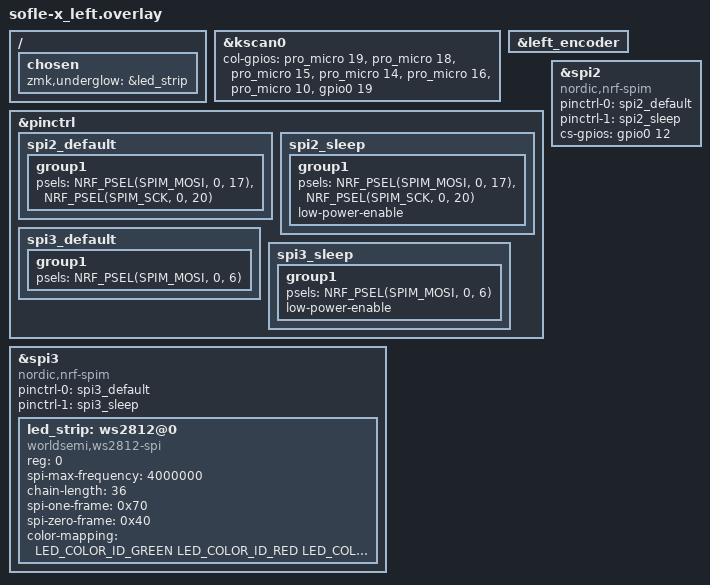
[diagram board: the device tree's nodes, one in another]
/*
 * Copyright (c) 2020 Ryan Cross
 *
 * SPDX-License-Identifier: MIT
 */

#include "sofle-x.dtsi"

&kscan0 {
    col-gpios
        = <&pro_micro 19 GPIO_ACTIVE_HIGH>
        , <&pro_micro 18 GPIO_ACTIVE_HIGH>
        , <&pro_micro 15 GPIO_ACTIVE_HIGH>
        , <&pro_micro 14 GPIO_ACTIVE_HIGH>
        , <&pro_micro 16 GPIO_ACTIVE_HIGH>
        , <&pro_micro 10 GPIO_ACTIVE_HIGH>
        , <&gpio0 19 GPIO_ACTIVE_HIGH>
        ;
};

&left_encoder {
    status = "okay";
};

#include <dt-bindings/led/led.h>


&pinctrl {
    spi2_default: spi2_default {
        group1 {
            psels = <NRF_PSEL(SPIM_MOSI, 0, 17)>,
            <NRF_PSEL(SPIM_SCK, 0, 20)>;
        };
    };
    spi2_sleep: spi2_sleep {
        group1 {
            psels = <NRF_PSEL(SPIM_MOSI, 0, 17)>,
            <NRF_PSEL(SPIM_SCK, 0, 20)>;
            low-power-enable;
        };
    };
};


lpm_view_spi: &spi2 {
    compatible = "nordic,nrf-spim";
    pinctrl-0 = <&spi2_default>;
    pinctrl-1 = <&spi2_sleep>;
    pinctrl-names = "default", "sleep";
    cs-gpios = <&gpio0 12 GPIO_ACTIVE_HIGH>;
};

nice_view_spi: &spi2 {
    compatible = "nordic,nrf-spim";
    pinctrl-0 = <&spi2_default>;
    pinctrl-1 = <&spi2_sleep>;
    pinctrl-names = "default", "sleep";
    cs-gpios = <&gpio0 12 GPIO_ACTIVE_HIGH>;
};

&pinctrl {
    spi3_default: spi3_default {
        group1 {
            psels = <NRF_PSEL(SPIM_MOSI, 0, 6)>;
        };
    };

    spi3_sleep: spi3_sleep {
        group1 {
            psels = <NRF_PSEL(SPIM_MOSI, 0, 6)>;
            low-power-enable;
        };
    };
};

&spi3 {
    compatible = "nordic,nrf-spim";
    status = "okay";

    pinctrl-0 = <&spi3_default>;
    pinctrl-1 = <&spi3_sleep>;
    pinctrl-names = "default", "sleep";

    led_strip: ws2812@0 {
        compatible = "worldsemi,ws2812-spi";

        /* SPI */
        reg = <0>; /* ignored, but necessary for SPI bindings */
        spi-max-frequency = <4000000>;

        /* WS2812 */
        chain-length = <36>; /* arbitrary; change at will */
        spi-one-frame = <0x70>;
        spi-zero-frame = <0x40>;

        color-mapping = <
            LED_COLOR_ID_GREEN
            LED_COLOR_ID_RED
            LED_COLOR_ID_BLUE
        >;
    };
};

/ {
    chosen {
        zmk,underglow = &led_strip;
    };
};
